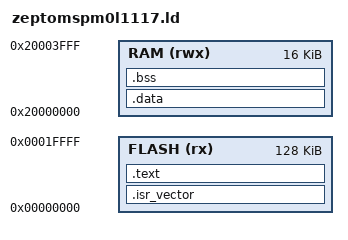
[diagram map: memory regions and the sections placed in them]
MEMORY
{
  FLASH (rx) : ORIGIN = 0x00000000, LENGTH = 128K
  RAM (rwx)  : ORIGIN = 0x20000000, LENGTH = 16K
}

ENTRY(Reset_Handler)

_estack = ORIGIN(RAM) + LENGTH(RAM);

SECTIONS
{
  .isr_vector :
  {
    KEEP(*(.isr_vector))
  } > FLASH

  .text :
  {
    *(.text*)
    *(.rodata*)
    . = ALIGN(4);
    _etext = .;
  } > FLASH

  .data : AT(_etext)
  {
    . = ALIGN(4);
    _sdata = .;
    *(.data*)
    . = ALIGN(4);
    _edata = .;
  } > RAM

  .bss (NOLOAD) :
  {
    . = ALIGN(4);
    _sbss = .;
    *(.bss*)
    *(COMMON)
    . = ALIGN(4);
    _ebss = .;
  } > RAM

  /DISCARD/ :
  {
    *(.comment)
    *(.note*)
    *(.eh_frame*)
    *(.ARM.exidx*)
    *(.ARM.extab*)
  }
}
